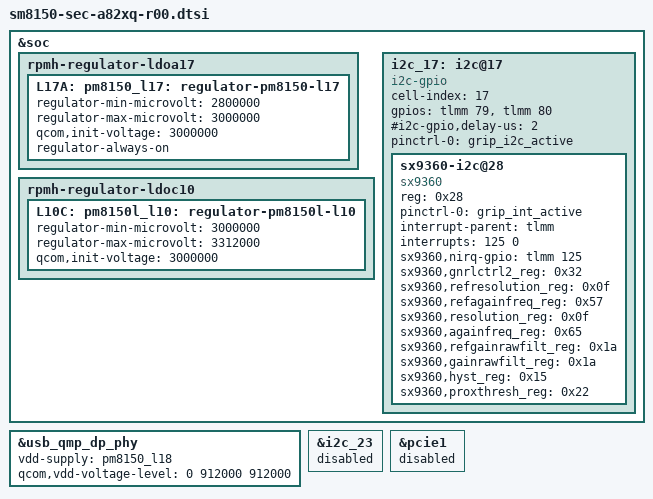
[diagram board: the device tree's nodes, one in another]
/* Copyright (c) 2016-2017, The Linux Foundation. All rights reserved.
 *
 * This program is free software; you can redistribute it and/or modify
 * it under the terms of the GNU General Public License version 2 and
 * only version 2 as published by the Free Software Foundation.
 *
 * This program is distributed in the hope that it will be useful,
 * but WITHOUT ANY WARRANTY; without even the implied warranty of
 * MERCHANTABILITY or FITNESS FOR A PARTICULAR PURPOSE.  See the
 * GNU General Public License for more details.
 */

#include "sm8150-sec-a82xq-common.dtsi"
#include "sm8150-sec-a82xq-audio.dtsi"
#include "sm8150-sec-a82xq-mst-r00.dtsi"
#include "sm8150-max77705.dtsi"

&soc {
	rpmh-regulator-ldoa17 {
		L17A: pm8150_l17: regulator-pm8150-l17 {
			regulator-min-microvolt = <2800000>;
			regulator-max-microvolt = <3000000>;
			qcom,init-voltage = <3000000>;
			regulator-always-on;
		};
	};

	/* for WIFI */
	rpmh-regulator-ldoc10 {
		L10C: pm8150l_l10: regulator-pm8150l-l10 {
			regulator-min-microvolt = <3000000>;
			regulator-max-microvolt = <3312000>;
			qcom,init-voltage = <3000000>;
		};
	};

	i2c_17: i2c@17 { /* SW I2C */
		status = "ok";

		cell-index = <17>;
		compatible = "i2c-gpio";
		gpios = <&tlmm 79 0 /* sda */
			 &tlmm 80 0 /* scl */
		>;
		#i2c-gpio,delay-us = <2>;
		#address-cells = <1>;
		#size-cells = <0>;
		pinctrl-names = "default";
		pinctrl-0 = <&grip_i2c_active>;

		sx9360-i2c@28 {
			compatible = "sx9360";
			reg = <0x28>;
			status = "okay";
			pinctrl-names = "default";
			pinctrl-0 = <&grip_int_active>;
			interrupt-parent = <&tlmm>;
			interrupts = <125 0>;

			sx9360,nirq-gpio = <&tlmm 125 0>;
			sx9360,gnrlctrl2_reg = <0x32>; /* scanperiod */
			sx9360,refresolution_reg = <0x0f>; /* same as resolution_reg */
			sx9360,refagainfreq_reg = <0x57>; /* same as againfreq_reg */
			sx9360,resolution_reg = <0x0f>; /* resolution : 1024 */
			sx9360,againfreq_reg = <0x65>; /* freq : 100.00 kHz, again : +/-9.0 pF */
			sx9360,refgainrawfilt_reg = <0x1a>; /* same as gainrawfilt_reg */
			sx9360,gainrawfilt_reg = <0x1a>; /* rawfilter : 1-1/4, gain : x4 */
			sx9360,hyst_reg = <0x15>; /* hysteresis : +/-6 %, debouncer : 2 samples */
			sx9360,proxthresh_reg = <0x22>; /* threshhold : 578 */
		};
	};
};

&usb_qmp_dp_phy {
	vdd-supply = <&pm8150_l18>;
	qcom,vdd-voltage-level = <0 912000 912000>;
};

&i2c_23 {
	status = "disabled";
};

&pcie1 {
	status = "disabled";
};
